# NUC122_v1 register map
File version: 1.0
Registers are 32-bit, read-write, reset 0x0 unless marked. A register's access mark holds for its fields unless they carry their own. Offsets are from the block's base; [hi:lo] are bit positions; {n}, {i} and the like mark numbered series; 'fields as' and 'values as' point back to an identical list.

## CLK — CLK Register Map
Base 0x50000200
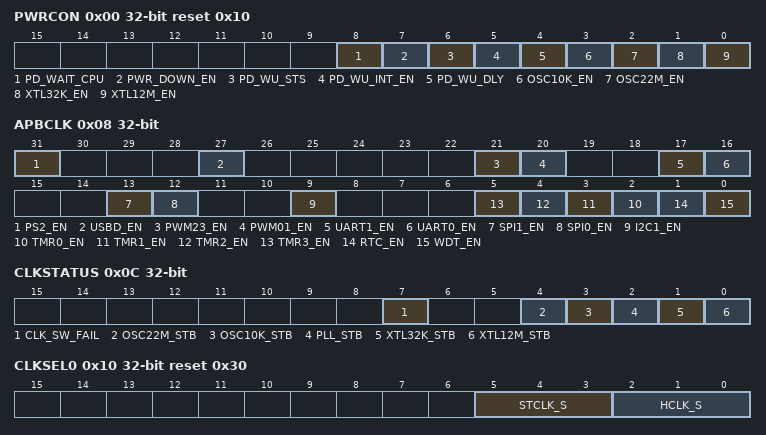
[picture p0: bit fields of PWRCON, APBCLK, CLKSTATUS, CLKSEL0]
0x00 PWRCON reset 0x10 (reset mask 0xFFFFFFF0) — System Power Down Control Register
  [8] PD_WAIT_CPU — This Bit Control the Power Down Entry Condition (write-protection bit)
    0=Chip entry power down mode when the PWR_DOWN_EN bit is set to 1; 1=Chip enter power down mode when the both PD_WAIT_CPU and PWR_DOWN_EN bits are set to 1 and CPU run WFI instruction
  [7] PWR_DOWN_EN — System Power Down Enable (write-protection bit). When this bit is set to 1, the chip power down mode is enabled and chip power down behavior will depends on the PD_WAIT_CPU bit (a) If the PD_WAIT_CPU is 0, then the chip enters power down mode immediately after the PWR_DOWN_EN bit set. (b) if the PD_WAIT_CPU is 1, then the chip keeps active till the CPU sleep mode is also active and then the chip enters power down mode. When chip be woken-up from power down mode, this bit is auto cleared. Users need to set this bit again for next power down. When in power down mode, external 4~24 MHz high speed crystal and the 22.1184 MHz high speed OSC will be disabled in this mode, but the 32.768 KHz low speed crystal and 10 KHz low speed OSC is not controlled by power down mode. When in power down mode, the PLL and system clock are disabled, and ignored the clock source selection. The clocks of peripheral are not controlled by power down mode, if the peripheral clock source is from 32.768 KHz low speed crystal or the 10 KHz low speed oscillator.
    0=Chip is operating normally or chip is in idle mode because of WFI command; 1=Chip enters the power down mode instant or wait CPU sleep command WFI
  [6] PD_WU_STS — Power Down Mode Wake-Up Interrupt Status. Set by "power down wake-up event", it indicates that resume from power down mode" The flag is set if the GPIO, USB, UART, WDT, BOD or RTC wake-up occurred. Write 1 to clear the bit to zero. Note: This bit is effective only if PD_WU_INT_EN (PWRCON[5]) be set to 1.
  [5] PD_WU_INT_EN — Power Down Mode Wake-Up Interrupt Enable (write-protection bit). The interrupt will occur when both PD_WU_STS and PD_WU_INT_EN are high.
    0=Disable; 1=Enable
  [4] PD_WU_DLY — Wake-Up Delay Counter Enable (write-protection bit). When the chip be woken-up from power down mode, the clock control will delay certain clock cycles to wait system clock is stable. The delayed clock cycle is 4096 clock cycles when chip work at external 4~24 MHz high speed crystal, and 256 clock cycles when chip work at 22.1184 MHz high speed oscillator.
    0=Disable clock cycles delay; 1=Enable clock cycles delay
  [3] OSC10K_EN — Internal 10 KHz Low Speed Oscillator Enable (write-protection bit)
    0=Disable 10 KHz low speed oscillator; 1=Enable 10 KHz low speed oscillator
  [2] OSC22M_EN — Internal 22.1184 MHz High Speed Oscillator Enable (write-protection bit)
    0=Disable 22.1184 MHz high speed oscillator; 1=Enable 22.1184 MHz high speed oscillator
  [1] XTL32K_EN — External 32.768 KHz Low Speed Crystal Enable (write-protection bit)
    0=Disable 32.768 KHz low speed crystal; 1=Enable 32.768 KHz low speed crystal (Normal operation)
  [0] XTL12M_EN — External 4~24 MHz High Speed Crystal Enable (write-protection bit). The bit default value is set by flash controller user configuration register config0 [26:24]. When the default clock source is from external 4~24 MHz high speed crystal, this bit is set to 1 automatically
    0=Disable external 4~24 MHz high speed crystal; 1=Enable external 4~24 MHz high speed crystal
0x04 AHBCLK reset 0xD — AHB Devices Clock Enable Control Register
  [2] ISP_EN — Flash ISP Controller Clock Enable Control
    0=Disable the Flash ISP engine clock; 1=Enable the Flash ISP engine clock
0x08 APBCLK (reset mask 0xFFFFFFF0) — APB Devices Clock Enable Control Register
  [31] PS2_EN — PS2 Clock Enable
    0=Disable PS/2 clock; 1=Enable PS/2 clock
  [27] USBD_EN — USB 2.0 FS Device Controller Clock Enable
    0=Disable USB clock; 1=Enable USB clock
  [21] PWM23_EN — PWM_23 Clock Enable
    0=Disable PWM23 clock; 1=Enable PWM23 clock
  [20] PWM01_EN — PWM_01 Clock Enable
    0=Disable PWM01 clock; 1=Enable PWM01 clock
  [17] UART1_EN — UART1 Clock Enable
    0=Disable UART1 clock; 1=Enable UART1 clock
  [16] UART0_EN — UART0 Clock Enable
    0=Disable UART0 clock; 1=Enable UART0 clock
  [13] SPI1_EN — SPI1 Clock Enable
    0=Disable SPI1 clock; 1=Enable SPI1 clock
  [12] SPI0_EN — SPI0 Clock Enable
    0=Disable SPI0 clock; 1=Enable SPI0 clock
  [9] I2C1_EN — I2C1 Clock Enable
    0=Disable I2C1 clock; 1=Enable I2C1 clock
  [n+2] TMR{n}_EN (n=0..3) — Timer{n} Clock Enable
    0=Disable Timer{n} clock; 1=Enable Timer{n} clock
  [1] RTC_EN — Real-Time-Clock APB interface Clock Enable. This bit is used to control the RTC APB clock only, The RTC engine clock source is from the 32768 Hz crystal.
    0=Disable RTC clock; 1=Enable RTC clock
  [0] WDT_EN — Watchdog Timer Clock Enable (write-protection bit). This bit is the protected bit. It means programming this needs to write "59h", "16h", "88h" to address 0x5000_0100 to disable register protection. Reference the register REGWRPROT at address GCR_BA+0x100.
    0=Disable Watchdog Timer clock; 1=Enable Watchdog Timer clock
0x0C CLKSTATUS (reset mask 0xFFFFFF00) — Clock Status Monitor Register
  [7] CLK_SW_FAIL — Clock Switching Fail Flag (write-protection bit). This bit is updated when software switches system clock source. If switch target clock is stable, this bit will be set to 0. If switch target clock is not stable, this bit will be set to 1. Write 1 to clear the bit to zero.
    0=Clock switching success; 1=Clock switching failure
  [4] OSC22M_STB — Internal 22.1184 MHz High Speed Oscillator Clock Source Stable Flag. This is read only bit
    0=Internal 22.1184 MHz high speed oscillator clock is not stable or disabled; 1=Internal 22.1184 MHz high speed oscillator clock is stable
  [3] OSC10K_STB — Internal 10 KHz Low Speed Oscillator Clock Source Stable Flag. This is read only bit
    0=Internal 10 KHz low speed oscillator clock is not stable or disabled; 1=Internal 10 KHz low speed oscillator clock is stable
  [2] PLL_STB — Internal PLL Clock Source Stable Flag. This is read only bit
    0=Internal PLL clock is not stable or disabled; 1=Internal PLL clock is stable
  [1] XTL32K_STB — External 32.768 KHz Low Speed Crystal Clock Source Stable Flag. This is read only bit
    0=External 32.768 KHz low speed crystal clock is not stable or disabled; 1=External 32.768 KHz low speed crystal clock is stable
  [0] XTL12M_STB — External 4~24 MHz High Speed Crystal Clock Source Stable Flag. This is read only bit
    0=External 4~24 MHz high speed crystal clock is not stable or disabled; 1=External 4~24 MHz high speed crystal clock is stable
0x10 CLKSEL0 reset 0x30 (reset mask 0xFFFFFFF0) — Clock Source Selection Control Register 0
  [5:3] STCLK_S — Cortex-M0 SysTick Clock Source Selection (write-protection bits)
    0=Clock source from external 4~24 MHz high speed crystal clock; 1=Clock source from external 32.768 KHz low speed crystal clock; 2=Clock source from external 4~24 MHz high speed crystal clock/2; 3=Clock source from HCLK/2; 7=Clock source from internal 22.1184 MHz high speed oscillator clock/2
  [2:0] HCLK_S — HCLK Clock Source Selection (write-protection bits). Note: Before clock switching, the related clock sources (both pre-select and new-select) must be turn on. The 3-bit default value is reloaded from the value of CFOSC (Config0[26:24]) in user configuration register of Flash controller by any reset. Therefore the default value is either 000b or 111b. These bits are protected bit, It means programming this bit needs to write "59h", "16h", "88h" to address 0x5000_0100 to disable register protection. Reference the register REGWRPROT at address GCR_BA+0x100.
    0=Clock source from external 4~24 MHz high speed crystal clock; 1=Clock source from external 32.768 KHz low speed crystal clock; 2=Clock source from PLL clock; 3=Clock source from internal 10 KHz low speed oscillator clock; 7=Clock source from internal 22.1184 MHz high speed oscillator clock
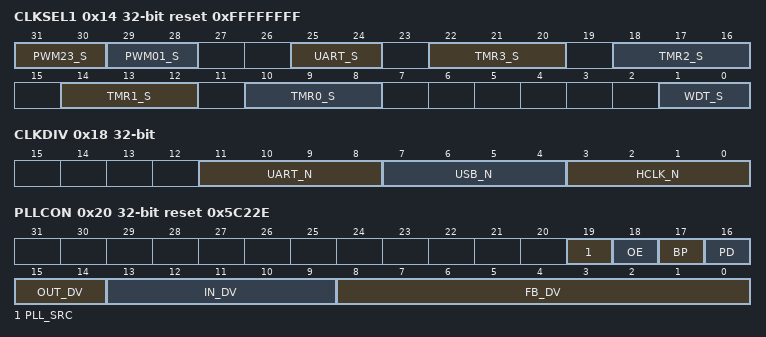
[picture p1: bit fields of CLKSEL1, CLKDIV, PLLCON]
0x14 CLKSEL1 reset 0xFFFFFFFF — Clock Source Selection Control Register 1
  [31:30] PWM23_S — PWM2 and PWM3 Clock Source Selection. PWM2 and PWM3 uses the same Engine clock source, both of them use the same prescaler
    0=Clock source from external 4~24 MHz high speed crystal clock; 1=Clock source from external 32.768 KHz low speed crystal clock; 2=Clock source from HCLK; 3=Clock source from internal 22.1184 MHz high speed oscillator clock
  [29:28] PWM01_S — PWM0 and PWM1 Clock Source Selection. PWM0 and PWM1 uses the same Engine clock source, both of them use the same prescaler
    values as PWM23_S
  [25:24] UART_S — UART Clock Source Selection
    0=Clock source from external 4~24 MHz high speed crystal clock; 1=Clock source from PLL clock; 3=Clock source from internal 22.1184 MHz high speed oscillator clock
  [4n+10:4n+8] TMR{n}_S (n=0..3) — TIMER{n} Clock Source Selection
    0=Clock source from external 4~24 MHz high speed crystal clock; 1=Clock source from external 32.768 KHz low speed crystal clock; 2=Clock source from HCLK; 7=Clock source from internal 22.1184 MHz high speed oscillator clock
  [1:0] WDT_S — Watchdog Timer Clock Source Selection (write-protection bits). These bits are protected-bit, program this need to write "59h", "16h", "88h" to address 0x5000_0100 to disable register protection. Reference the register REGWRPROT at address GCR_BA+0x100.
    2=Clock source from HCLK/2048 clock; 3=Clock source from internal 10 KHz low speed oscillator clock
0x18 CLKDIV — Clock Divider Register
  [11:8] UART_N — UART Clock Divider from UART Clock Source
  [7:4] USB_N — USB Clock Divider from PLL Clock Source
  [3:0] HCLK_N — HCLK Clock Divider from HCLK Clock Source
0x20 PLLCON reset 0x5C22E — PLL Control Register
  [19] PLL_SRC — PLL Source Clock Selection
    0=PLL source clock from external 4~24 MHz high speed crystal; 1=PLL source clock from internal 22.1184 MHz high speed oscillator
  [18] OE — PLL OE (FOUT enable)
    0=PLL FOUT enable; 1=PLL FOUT is fixed low
  [17] BP — PLL Bypass Control
    0=PLL is in normal mode (default); 1=PLL clock output is same as clock input (XTALin)
  [16] PD — Power Down Mode. If set the PWR_DOWN_EN bit to 1 in PWRCON register, the PLL will enter power down mode too.
    0=PLL is in normal mode; 1=PLL is in power down mode (default)
  [15:14] OUT_DV — PLL Output Divider. Refer to the formulas below the table.
  [13:9] IN_DV — PLL Input Divider. Refer to the formulas below the table.
  [8:0] FB_DV — PLL Feedback Divider. Refer to the formulas below the table.
